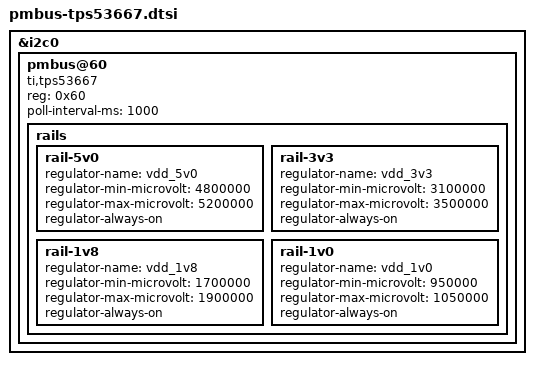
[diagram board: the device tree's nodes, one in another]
/* TPS53667 PMBus rails: 5V0, 3V3, 1V8, 1V0 — telemetry polling interval & address placeholders. */

&i2c0 {
	status = "okay";
	
	/* TPS53667 PMBus Power Management Controller */
	pmbus@60 {
		compatible = "ti,tps53667";
		reg = <0x60>;
		
		/* Power rails from 12V slot input via MPS MP86992 VRMs */
		rails {
			/* 5V0 rail */
			rail-5v0 {
				regulator-name = "vdd_5v0";
				regulator-min-microvolt = <4800000>;
				regulator-max-microvolt = <5200000>;
				regulator-always-on;
			};
			
			/* 3V3 rail */
			rail-3v3 {
				regulator-name = "vdd_3v3";
				regulator-min-microvolt = <3100000>;
				regulator-max-microvolt = <3500000>;
				regulator-always-on;
			};
			
			/* 1V8 rail */
			rail-1v8 {
				regulator-name = "vdd_1v8";
				regulator-min-microvolt = <1700000>;
				regulator-max-microvolt = <1900000>;
				regulator-always-on;
			};
			
			/* 1V0 rail */
			rail-1v0 {
				regulator-name = "vdd_1v0";
				regulator-min-microvolt = <950000>;
				regulator-max-microvolt = <1050000>;
				regulator-always-on;
			};
		};
		
		/* Telemetry polling interval (milliseconds) */
		poll-interval-ms = <1000>;
	};
};

